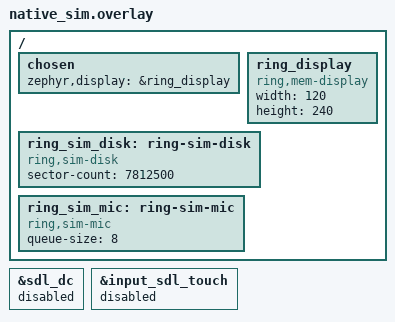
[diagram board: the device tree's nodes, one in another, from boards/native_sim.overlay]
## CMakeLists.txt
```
cmake_minimum_required(VERSION 3.20.0)

# The recorder's suites (software step 6, unit J): the real core, glue, screens and every unit of step 6 on the simulated
# drivers of ring_rhw. RING_RECORDER_DIR lets broken_run.sh point at a broken copy of ring_recorder to prove that these tests
# can fail: west twister ... --extra-args RING_RECORDER_DIR=<copy>
set(MOD ${CMAKE_CURRENT_SOURCE_DIR}/../../modules)
if(NOT DEFINED RING_RECORDER_DIR)
  set(RING_RECORDER_DIR ${MOD}/ring_recorder)
endif()
list(APPEND ZEPHYR_EXTRA_MODULES ${MOD}/ring_rhw ${MOD}/ring_core ${MOD}/ring_control ${MOD}/ring_devices ${MOD}/ring_inbox
  ${MOD}/ring_time ${MOD}/ring_iphone ${MOD}/ring_glue ${MOD}/ring_screens ${MOD}/ring_store ${MOD}/ring_audio
  ${MOD}/ring_xfer ${MOD}/ring_power ${MOD}/ring_motor ${MOD}/ring_sys ${MOD}/ring_factory ${RING_RECORDER_DIR})

find_package(Zephyr REQUIRED HINTS $ENV{ZEPHYR_BASE})
project(ring_recorder_tests)

target_include_directories(app PRIVATE src)
# RT_SUITE=<file> (without .c) builds the harness and that one suite file only: broken_run.sh uses it so that each broken
# copy runs the suite of its named case.
if(DEFINED RT_SUITE)
  target_sources(app PRIVATE src/rt.c src/${RT_SUITE}.c)
else()
target_sources(app PRIVATE
  src/rt.c
  src/test_rows.c
  src/test_actions.c
  src/test_boot.c
  src/test_sign.c
  src/test_sign1.c
  src/test_sequence.c
  src/test_rails.c
  src/test_rules.c
  src/test_log.c
  src/test_screens.c
  src/test_ship.c
  src/test_unmount.c
  src/test_factory.c
  src/test_noscreens.c)
endif()
```

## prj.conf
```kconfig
CONFIG_ZTEST=y
CONFIG_ZTEST_STACK_SIZE=16384
CONFIG_MAIN_STACK_SIZE=8192
CONFIG_THREAD_NAME=y
CONFIG_HEAP_MEM_POOL_SIZE=4096

# the glue needs the control part, which needs Bluetooth with the HID service (as in the product); nothing here enables
# Bluetooth (no bt_enable): the radio is not part of these suites
CONFIG_BT=y
CONFIG_BT_PERIPHERAL=y
CONFIG_BT_DEVICE_NAME="Ring"
CONFIG_BT_MAX_CONN=1
CONFIG_BT_MAX_PAIRED=3
CONFIG_BT_ID_MAX=3
CONFIG_BT_SMP=y
CONFIG_BT_SMP_SC_ONLY=y
CONFIG_BT_SMP_APP_PAIRING_ACCEPT=y
CONFIG_BT_GATT_AUTO_SEC_REQ=n
CONFIG_BT_AUTO_PHY_UPDATE=n
CONFIG_BT_HIDS_DEFAULT_PERM_RW_AUTHEN=y
CONFIG_BT_CONN_CTX=y
CONFIG_BT_HIDS=y
CONFIG_BT_HIDS_INPUT_REP_MAX=3
CONFIG_BT_HIDS_OUTPUT_REP_MAX=0
CONFIG_BT_HIDS_FEATURE_REP_MAX=0
CONFIG_BT_HIDS_ATTR_MAX=24
CONFIG_BT_HIDS_MAX_CLIENT_COUNT=1
CONFIG_BT_GATT_UUID16_POOL_SIZE=40
CONFIG_BT_GATT_CHRC_POOL_SIZE=20

CONFIG_RING_CORE=y
CONFIG_RING_DEVICES=y
CONFIG_RING_CONTROL=y
CONFIG_RING_GLUE=y
CONFIG_RING_GLUE_STACK_SIZE=8192
CONFIG_RING_INBOX=y
CONFIG_RING_TIME=y

# the screens on the memory display, with the read-back hooks
CONFIG_RING_SCREENS=y
CONFIG_RING_SCREENS_CAPTURE=y
CONFIG_RING_SCREENS_SIGN_WAIT_MS=2000
CONFIG_LVGL=y
CONFIG_LV_Z_AUTO_INIT=n
CONFIG_LV_COLOR_DEPTH_16=y
CONFIG_LV_FONT_MONTSERRAT_14=y
CONFIG_LV_FONT_MONTSERRAT_16=y
CONFIG_LV_FONT_MONTSERRAT_28=y
CONFIG_LV_FONT_MONTSERRAT_32=y
CONFIG_LV_Z_MEM_POOL_SIZE=32768
CONFIG_RING_SCREENS_STACK_SIZE=8192

# the recorder parts on the simulated drivers
CONFIG_RING_RHW=y
CONFIG_RING_RHW_SIM=y
CONFIG_RING_STORE=y
CONFIG_RING_AUDIO=y
CONFIG_RING_XFER=y
CONFIG_RING_POWER=y
CONFIG_RING_MOTOR=y
CONFIG_RING_SYS=y
CONFIG_RING_FACTORY=y
CONFIG_RING_RECORDER=y
CONFIG_RING_RECORDER_TEST_HOOKS=y
CONFIG_SYSTEM_WORKQUEUE_STACK_SIZE=4096
# a test card: each case starts on an empty card; the longest recording of a case (about 25 chunks) and the log fit
CONFIG_RING_RHW_SIM_DISK_POOL=6000
CONFIG_RING_RHW_SIM_LOG_SIZE=16384
```

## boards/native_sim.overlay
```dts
/* The recorder's suites: the memory display of the screens part (the SDL display of native_sim off), the simulated card and the
 * simulated microphone input of ring_rhw. No chip pin is named here. */
/ {
	chosen {
		zephyr,display = &ring_display;
	};
	ring_display: ring_display {
		compatible = "ring,mem-display";
		width = <120>;
		height = <240>;
	};
	ring_sim_disk: ring-sim-disk {
		compatible = "ring,sim-disk";
		sector-count = <7812500>;
	};
	ring_sim_mic: ring-sim-mic {
		compatible = "ring,sim-mic";
		queue-size = <8>;
	};
};

&sdl_dc {
	status = "disabled";
};

&input_sdl_touch {
	status = "disabled";
};
```

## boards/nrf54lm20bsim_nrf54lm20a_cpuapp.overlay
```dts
/* The recorder's suites on the simulated chip: the memory display of the screens part, the simulated card and the simulated
 * microphone input of ring_rhw. No chip pin is named here. */
/ {
	chosen {
		zephyr,display = &ring_display;
	};
	ring_display: ring_display {
		compatible = "ring,mem-display";
		width = <120>;
		height = <240>;
	};
	ring_sim_disk: ring-sim-disk {
		compatible = "ring,sim-disk";
		sector-count = <7812500>;
	};
	ring_sim_mic: ring-sim-mic {
		compatible = "ring,sim-mic";
		queue-size = <8>;
	};
};
```

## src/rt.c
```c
/* rt.c: the harness of the recorder's suites (see rt.h). */
#include <errno.h>
#include <string.h>

#include <zephyr/sys/byteorder.h>
#include <zephyr/sys/crc.h>

#include <ring_devices/rdev_logic.h>
#include <ring_inbox/rinbox.h>
#include <ring_iphone/ripl.h>
#include <ring_core/rc_sm.h>

#include "rt.h"

/* ------------------------------------------------------------------ logs of the wrappers */
#define STEPS_MAX 512
#define ACTS_MAX 1024
static struct rt_step steps[STEPS_MAX];
static uint32_t n_steps;
static struct rt_act acts[ACTS_MAX];
static uint32_t n_acts;
static uint32_t mic_at_screens;
static uint32_t screens_told;

uint32_t rt_steps(void)
{
	return MIN(n_steps, STEPS_MAX);
}

struct rt_step rt_step_get(uint32_t i)
{
	return steps[i];
}

bool rt_row_seen(int row)
{
	for (uint32_t i = 0; i < rt_steps(); i++) {
		if (steps[i].row == row) {
			return true;
		}
	}
	return false;
}

void rt_steps_clear(void)
{
	n_steps = 0;
	n_acts = 0;
	mic_at_screens = 0;
	screens_told = 0;
}

uint32_t rt_acts(void)
{
	return MIN(n_acts, ACTS_MAX);
}

struct rt_act rt_act_get(uint32_t i)
{
	return acts[i];
}

uint32_t rt_mic_at_screens(void)
{
	return mic_at_screens;
}

uint32_t rt_screens_told(void)
{
	return screens_told;
}

/* the product's glue ops (app/src/main.c), each wrapped to keep a log */
static void w_action(enum rc_action a, rc_ms_t t)
{
	if (n_acts < ACTS_MAX) {
		acts[n_acts].a = (uint8_t)a;
		acts[n_acts].t_ms = t;   /* the time of the core step the glue gives */
	}
	n_acts++;
	rrec_action(a, t);
}

static bool w_after(const struct rc_actions *a, enum rc_event ev, enum rc_state st, rc_ms_t t)
{
	if (n_steps < STEPS_MAX) {
		steps[n_steps].row = a->last_row;
		steps[n_steps].ev = (uint8_t)ev;
		steps[n_steps].state = (uint8_t)st;
		steps[n_steps].t_ms = k_uptime_get();
	}
	n_steps++;
	return rrec_glue_after(a, ev, st, t);
}

static const struct rglue_ops gops = {
	.action = w_action,
	.after = w_after,
	.screen_fact = rrec_glue_screen_fact,
	.sign_start = rrec_sign_hook,
	.factory_gesture = rrec_factory_gesture,
};

/* ------------------------------------------------------------------ stand-in reads of the screens (no inbox, no devices) */
static uint8_t o_inbox_count(void)
{
	return 0;
}

static bool o_inbox_get(uint8_t i, struct rinbox_item *o)
{
	ARG_UNUSED(i);
	ARG_UNUSED(o);
	return false;
}

static void o_media_get(struct ripl_media *o)
{
	ripl_media_init(o);
}

static bool o_ams_ready(void)
{
	return false;
}

/* called inside rscr_glue_after (load_view): the moment the screens learn of a core state */
static uint8_t o_paired(void)
{
	k_tid_t me = k_current_get();
	const char *nm = k_thread_name_get(me);

	if (me != rscr_thread_id() && (nm == NULL || strcmp(nm, "rpw") != 0)) {
		screens_told++;
		if (rc_core_state(rglue_core()) != RC_ST_RECORDING && rhw_pmic()->rail_get(RHW_RAIL_MIC) &&
		    atomic_get(&rrec_st.test_recording) == 0) {
			mic_at_screens++;
		}
	}
	return 0;
}

static uint8_t o_active(void)
{
	return RDEV_NONE;
}

static bool o_link(void)
{
	return false;
}

static int o_uid(uint32_t uid)
{
	ARG_UNUSED(uid);
	return 0;
}

static int o_slot(uint8_t slot)
{
	ARG_UNUSED(slot);
	return 0;
}

static void o_void(void)
{
}

static void o_bool(bool on)
{
	ARG_UNUSED(on);
}

static void o_mode(enum rctl_mode m)
{
	ARG_UNUSED(m);
}

static int o_power_off(void)
{
	return rglue_event_try(RC_EV_MENU_POWER_OFF);   /* the product's rule: -EBUSY when the glue is busy */
}

static const struct rscr_ops sops = {
	.inbox_count = o_inbox_count, .inbox_get = o_inbox_get, .media_get = o_media_get, .ams_ready = o_ams_ready,
	.paired_mask = o_paired, .active = o_active, .link_up = o_link, .dismiss = o_uid, .positive = o_uid,
	.mark_read = o_uid, .pair_open = o_slot, .pair_cancel = o_void, .dev_use = o_slot, .dev_remove = o_slot,
	.control_active = o_bool, .set_mode = o_mode, .power_off = o_power_off, .vibration = o_bool, .now_ms = NULL,
};

/* ------------------------------------------------------------------ world */
void rt_sleep(int32_t ms)
{
	k_sleep(K_MSEC(ms));
}

void rt_settle(void)
{
	int quiet = 0;

	for (int i = 0; i < 1000 && quiet < 3; i++) {
		k_sleep(K_MSEC(20));
		quiet = rrec_idle() ? quiet + 1 : 0;
	}
}

static bool glue_started;
bool rt_screens_started;

void rt_setup(void)
{
	if (!rt_screens_started) {
		rt_screens_started = true;
		zassert_equal(rscr_start(&sops), 0, "screens start on the memory display");
	}
	if (!glue_started) {
		glue_started = true;
		rglue_init(&gops, RC_ST_BOOT);
	}
}

void rt_setup_no_screens(void)
{
	if (!glue_started) {
		glue_started = true;
		rglue_init(&gops, RC_ST_BOOT);
	}
}

void rt_core_at(enum rc_state s)
{
	rc_core_init(rglue_core(), RC_CENTRE_SW2, s, k_uptime_get());
	rc_core_set_sign_hook(rglue_core(), rrec_sign_hook, NULL);
	rrec_st.core_state = (uint8_t)s;
}

static void apply(const struct rt_boot *b)
{
	static struct rhw_pmic_sample sc[2];
	struct rhw_persist p;

	if (b == NULL) {
		return;
	}
	if (b->chunks != 0) {
		rhw_sim_disk_set_sectors(RREC_LBA_CHUNK_FIRST + b->chunks * RREC_CHUNK_SECTORS);
	}
	if (b->init_fail != 0) {
		rhw_sim_disk_fail_init(b->init_fail);
	}
	if (b->mv != 0) {
		for (int i = 0; i < 2; i++) {
			sc[i].mv = i == 0 ? b->mv : (b->mv_next != 0 ? b->mv_next : b->mv);
			sc[i].ua = b->ua != 0 ? b->ua : 3000;
			sc[i].temp_c_x10 = 250;
			sc[i].die_c_x10 = 300;
		}
		rhw_sim_pmic_script(sc, 2);
	}
	if (b->chg_forced != 0) {
		rhw_sim_pmic_charge_state((int)b->chg_forced - 1);
	}
	if (b->gauge_uah != 0) {
		rhw_sim_gauge_capacity(b->gauge_uah);
	}
	if (b->soc_x10 != 0) {
		rhw_sim_gauge_start_soc(b->soc_x10);
	}
	if (b->factory_flag) {
		memset(&p, 0, sizeof(p));
		p.factory_flag = 1;
		rhw_sim_persist_set(&p);
	}
	if (b->vbus) {
		rhw_sim_pmic_vbus(true);
	}
	if (b->unconfirmed) {
		rhw_sim_image_set_confirmed(false);
	}
}

static void boot_now(const struct rt_boot *b)
{
	rhw_sim_log_clear();
	rrec_tap_clear();
	rt_steps_clear();
	rt_core_at(RC_ST_BOOT);
	(void)rrec_boot();
	if (b != NULL && b->vbus) {
		rhw_sim_usb_event(RHW_USB_VBUS_READY);   /* the controller reports VBUS at its start (the class enables the stack) */
	}
	rt_settle();
}

void rt_fresh(const struct rt_boot *b)
{
	rt_settle();
	rmd_inject_fail(0);
	rscr_test_force_down(false);
	rt_sleep(50);
	rhw_sim_reset();
	rhw_sim_reboot();   /* every unit's RAM state back to reset values (the audio part waits for its capture loop, F1) */
	apply(b);
	boot_now(b);
}

void rt_reboot(const struct rt_boot *b)
{
	rt_sleep(100);
	rhw_sim_reboot();   /* the audio part waits for its capture loop (finding F1): no sleep after it */
	apply(b);
	boot_now(b);
}

void rt_long(void)
{
	rglue_input(RC_SW_CENTRE, true);
	rt_sleep(1100);
	rglue_input(RC_SW_CENTRE, false);
	rt_sleep(100);
	rt_settle();
}

void rt_short(void)
{
	rglue_input(RC_SW_CENTRE, true);
	rt_sleep(100);
	rglue_input(RC_SW_CENTRE, false);
	rt_sleep(500);
	rt_settle();
}

void rt_double(void)
{
	rglue_input(RC_SW_CENTRE, true);
	rt_sleep(100);
	rglue_input(RC_SW_CENTRE, false);
	rt_sleep(150);
	rglue_input(RC_SW_CENTRE, true);
	rt_sleep(100);
	rglue_input(RC_SW_CENTRE, false);
	rt_sleep(500);
	rt_settle();
}

void rt_vbus(bool on)
{
	rhw_sim_vbus(on);
	rt_sleep(50);
	rt_settle();
}

void rt_usb_ready(void)
{
	rhw_sim_usb_event(RHW_USB_VBUS_READY);
	rt_settle();
}

void rt_usb_configured(void)
{
	rhw_sim_usb_event(RHW_USB_CONFIGURED);
	rt_sleep(20);
	rt_settle();
}

int rt_usb_send(uint8_t op, const uint8_t *pl, uint32_t len)
{
	static uint8_t req[RREC_MSG_HEADER_BYTES + RREC_FW_DATA_MAX + 16];
	static uint32_t tag = 0x1000;
	static uint8_t junk[256];

	while (rhw_sim_usb_host_read(junk, sizeof(junk)) > 0) {
	}
	tag++;
	sys_put_le16(RREC_MSG_MAGIC, &req[RREC_MSG_OFF_MAGIC]);
	req[RREC_MSG_OFF_OPCODE] = op;
	req[RREC_MSG_OFF_STATUS] = 0;
	sys_put_le32(tag, &req[RREC_MSG_OFF_TAG]);
	sys_put_le32(len, &req[RREC_MSG_OFF_LENGTH]);
	sys_put_le32(len != 0 ? crc32_ieee(pl, len) : 0, &req[RREC_MSG_OFF_CRC]);
	if (len != 0) {
		memcpy(&req[RREC_MSG_HEADER_BYTES], pl, len);
	}
	return rhw_sim_usb_host_write(req, RREC_MSG_HEADER_BYTES + len);
}

int rt_usb_recv(uint8_t *resp, size_t max, uint8_t *st, int32_t timeout_ms)
{
	size_t n = 0;
	uint32_t want;

	for (int32_t w = 0; w < timeout_ms; w += 10) {
		k_sleep(K_MSEC(10));
		n += rhw_sim_usb_host_read(&resp[n], max - n);
		if (n >= RREC_MSG_HEADER_BYTES) {
			want = RREC_MSG_HEADER_BYTES + sys_get_le32(&resp[RREC_MSG_OFF_LENGTH]);
			if (n >= want || n >= max) {
				break;
			}
		}
	}
	*st = n >= RREC_MSG_HEADER_BYTES ? resp[RREC_MSG_OFF_STATUS] : 0xFE;
	return (int)n;
}

int rt_usb(uint8_t op, const uint8_t *pl, uint32_t len, uint8_t *resp, size_t max, uint8_t *st)
{
	int n;

	if (rt_usb_send(op, pl, len) != 0) {
		*st = 0xFF;
		return -ENODEV;
	}
	n = rt_usb_recv(resp, max, st, 15000);
	rt_sleep(20);
	rt_settle();
	return n;
}

void rt_samples(uint16_t mv)
{
	static struct rhw_pmic_sample s;

	s.mv = mv;
	s.ua = 3000;
	s.temp_c_x10 = 250;
	s.die_c_x10 = 300;
	rhw_sim_pmic_script(&s, 1);
}

enum rc_state rt_state(void)
{
	/* read without the glue's lock: ship mode holds the lock while it waits for VBUS removal (FW l.939) */
	return rc_core_state(rglue_core());
}

bool rt_mic(void)
{
	return rhw_pmic()->rail_get(RHW_RAIL_MIC);
}

bool rt_sd(void)
{
	return rhw_pmic()->rail_get(RHW_RAIL_SD);
}

/* ------------------------------------------------------------------ the simulated event log */
int32_t rt_find(uint16_t kind, int64_t a0, int64_t a1, uint32_t from)
{
	struct rhw_sim_ev e;

	for (uint32_t i = from; rhw_sim_log_get(i, &e); i++) {
		if (e.kind == kind && (a0 < 0 || e.a0 == a0) && (a1 < 0 || e.a1 == a1)) {
			return (int32_t)i;
		}
	}
	return -1;
}

int32_t rt_find_rail(enum rhw_rail rail, bool on, uint32_t from)
{
	return rt_find(RHW_EV_PMIC_RAIL, rail, on ? 1 : 0, from);
}

int64_t rt_ev_us(int32_t i)
{
	struct rhw_sim_ev e;

	if (i < 0 || !rhw_sim_log_get((uint32_t)i, &e)) {
		return -1;
	}
	return e.t_us;
}

uint32_t rt_count_rail(enum rhw_rail rail, bool on)
{
	uint32_t n = 0;

	for (int32_t i = rt_find_rail(rail, on, 0); i >= 0; i = rt_find_rail(rail, on, (uint32_t)i + 1)) {
		n++;
	}
	return n;
}

/* ------------------------------------------------------------------ the display */
static uint8_t pic[RSCR_W * RSCR_H * 3];

bool rt_red_dot(void)
{
	int n = 0;

	rscr_sync();
	rscr_capture_rgb(pic);
	/* the red dot of SCR_RECORDING and SCR_REC_DIM: x 14 to 30, y 84 to 100 (tests/screens, test_draw.c) */
	for (int y = 84; y <= 100; y++) {
		for (int x = 14; x <= 30; x++) {
			const uint8_t *p = &pic[(y * RSCR_W + x) * 3];

			n += (p[0] > 200 && p[1] < 100 && p[2] < 100) ? 1 : 0;
		}
	}
	return n >= 40;
}

bool rt_blanked(void)
{
	struct rmd_stats m;

	rscr_sync();
	rmd_stats_get(&m);
	return m.blanked;
}

/* ------------------------------------------------------------------ rows of FW 1.2 */
const struct rc_row *rt_row(int row)
{
	for (uint16_t i = 0; i < rc_table_rows; i++) {
		if (rc_table[i].row == row) {
			return &rc_table[i];
		}
	}
	return NULL;
}

bool rt_cut_seen;

/* a card whose superblock says a recording was open: a recording, then the power cut (later writes lost) */
static void open_flag_card(void)
{
	rt_fresh(NULL);
	rt_long();
	rt_sleep(300);
	rhw_sim_disk_cut(1, 0);
	rt_sleep(800);
	rt_cut_seen = rhw_sim_disk_was_cut();   /* read before the reboot, which ends the cut (rhw_sim.h) */
}

/* the LBA of the open recording's first chunk, from the superblock on the simulated card (FW l.594, l.597, l.606, l.531):
 * the valid copy with the higher sb_seq (magic checked; the CRC is the store's business) */
static uint32_t open_first_chunk_lba(void)
{
	static uint8_t s[2][RREC_SECTOR_BYTES];
	int pick = -1;

	rhw_sim_disk_peek(RREC_LBA_SB_A, s[0]);
	rhw_sim_disk_peek(RREC_LBA_SB_B, s[1]);
	for (int i = 0; i < 2; i++) {
		if (sys_get_le32(&s[i][RREC_SB_OFF_MAGIC]) != RREC_SB_MAGIC) {
			continue;
		}
		if (pick < 0 || sys_get_le32(&s[i][RREC_SB_OFF_SB_SEQ]) > sys_get_le32(&s[pick][RREC_SB_OFF_SB_SEQ])) {
			pick = i;
		}
	}
	if (pick < 0) {
		return RREC_LBA_CHUNK_FIRST;
	}
	return RREC_LBA_CHUNK_FIRST + (sys_get_le32(&s[pick][RREC_SB_OFF_OPEN_FIRST_CHUNK]) %
				       sys_get_le32(&s[pick][RREC_SB_OFF_CHUNK_COUNT_TOTAL])) * RREC_CHUNK_SECTORS;
}

static void to_transfer(void)
{
	rt_vbus(true);
	rt_usb_configured();
}

static void fw_end_sequence(void)
{
	static uint8_t resp[64];
	static const uint8_t img[64] = { 1, 2, 3, 4, 5, 6, 7, 8 };
	uint8_t pl[8 + sizeof(img)];
	uint8_t st;

	sys_put_le32(sizeof(img), pl);
	sys_put_le32(crc32_ieee(img, sizeof(img)), &pl[4]);
	(void)rt_usb(RREC_OP_FW_BEGIN, pl, 8, resp, sizeof(resp), &st);
	sys_put_le32(0, pl);
	memcpy(&pl[4], img, sizeof(img));
	(void)rt_usb(RREC_OP_FW_DATA, pl, 4 + sizeof(img), resp, sizeof(resp), &st);
	(void)rt_usb(RREC_OP_FW_END, NULL, 0, resp, sizeof(resp), &st);
}

#if defined(CONFIG_RING_FACTORY)
static void factory_cmd(uint8_t sub)
{
	static uint8_t resp[512];
	uint8_t st;

	(void)rt_usb(RREC_OP_FACTORY, &sub, 1, resp, sizeof(resp), &st);
}

static void to_factory(void)
{
	struct rt_boot b = { .factory_flag = true };

	rt_fresh(&b);
	to_transfer();
	factory_cmd(RREC_FAC_ENTER);
}
#endif

static void mic_fault(void)
{
	rt_fresh(NULL);
	rt_long();
	for (int i = 0; i < 3 && rt_state() == RC_ST_RECORDING; i++) {
		uint32_t d = rhw_sim_mic_delivered();

		rhw_sim_mic_stop_after((int32_t)d + 2);
		rt_sleep(600);
		rt_settle();
		TC_PRINT("mic fault: try %d, blocks delivered %u, state %s, FAULT_MIC records %u, recorder idle %d\n", i + 1, d,
			 rc_state_name(rt_state()), rrec_tap_count_code(RREC_LOG_FAULT_MIC), rrec_idle());
	}
}

static void to_charger_error(void)
{
	struct rt_boot b = { .mv = 3900, .mv_next = 3250 };

	rt_fresh(&b);
	rt_vbus(true);
	rhw_sim_pmic_charge_error(1, 2);
	rt_sleep(50);
	rt_settle();
}

int rt_run_row(int row)
{
	struct rt_boot b;

	memset(&b, 0, sizeof(b));
	switch (row) {
	case 1:  /* SHIP, VBUS appears (the core's model; on the ring the chip starts from no power) */
	case 2:  /* OFF, VBUS appears */
		rt_fresh(NULL);
		rt_core_at(row == 1 ? RC_ST_SHIP : RC_ST_OFF);
		rt_steps_clear();
		rt_vbus(true);
		break;
	case 3:
		rt_fresh(NULL);
		break;
	case 4:
	case 9:
		open_flag_card();
		rt_reboot(NULL);
		break;
	case 5:
		b.vbus = true;
		rt_fresh(&b);
		break;
	case 6:
		b.init_fail = 3;
		rt_fresh(&b);
		break;
	case 7:
		b.mv = 3250;     /* at or under 3.30 V: B2 (FW l.117) */
		rt_fresh(&b);
		break;
	case 8:
		b.mv = 3400;     /* at or under 3.45 V: B5 (FW l.116) */
		rt_fresh(&b);
		break;
	case 10:
		open_flag_card();
		b.vbus = true;
		rt_reboot(&b);
		break;
	case 11:
		open_flag_card();
		rhw_sim_disk_read_error_at(open_first_chunk_lba());   /* the first chunk the scan reads */
		TC_PRINT("row 11: read error set at LBA %u (the open recording's first chunk)\n", open_first_chunk_lba());
		rt_reboot(NULL);
		break;
	case 12:
		rt_fresh(NULL);
		rt_long();
		break;
	case 13:  /* STANDBY with the open flag set (the fact the caller owns) */
		rt_fresh(NULL);
		rrec_st.fact_open = true;
		rrec_st.fact_open_pending = true;
		rt_long();
		break;
	case 14:  /* STANDBY with the battery fact at B5 */
		rt_fresh(NULL);
		rglue_core()->facts.batt = RC_BATT_B5;
		rt_long();
		break;
	case 15:  /* STANDBY with free space at SFULL: a card of 16 chunks, the core started in STANDBY with the fact */
		b.chunks = RREC_SFULL_CHUNKS;
		rt_fresh(&b);
		rt_core_at(RC_ST_STANDBY);
		rglue_core()->facts.storage_full = true;
		rt_long();
		break;
	case 16:
		rt_fresh(NULL);
		rscr_test_force_down(true);   /* the screens refuse the sign */
		rt_long();
		break;
	case 17:
		rt_fresh(NULL);
		rt_short();
		break;
	case 18:
		rt_fresh(NULL);
		rt_double();
		break;
	case 19:
		rt_fresh(NULL);
		rglue_event(RC_EV_MENU_POWER_OFF);
		rt_settle();
		break;
	case 20:
		rt_fresh(NULL);
		rt_vbus(true);
		break;
	case 21:
		b.soc_x10 = 151;   /* just above 15 % (FW l.115) */
		b.gauge_uah = 1000;
		rt_fresh(&b);
		rt_sleep(61000);
		rt_settle();
		break;
	case 22:
		b.mv = 3900;
		b.mv_next = 3400;
		rt_fresh(&b);
		rt_sleep(61000);
		rt_settle();
		break;
	case 23:
		b.mv = 3900;
		b.mv_next = 3250;
		rt_fresh(&b);
		rt_sleep(61000);
		rt_settle();
		break;
	case 24:
		b.chunks = RREC_SFULL_CHUNKS;
		rt_fresh(&b);
		break;
	case 25:
		b.init_fail = 1000;
		rt_fresh(&b);
		rt_vbus(true);
		rt_vbus(false);
		break;
	case 26:
		rt_fresh(NULL);
		rt_long();
		rt_sleep(1000);
		rt_long();
		break;
	case 27:
		rt_fresh(NULL);
		rt_long();
		rt_short();
		break;
	case 28:
		rt_fresh(NULL);
		rt_long();
		rt_double();
		break;
	case 29:
		rt_fresh(NULL);
		rt_long();
		rglue_event(RC_EV_BLE_HIGHLIGHT);
		rt_settle();
		break;
	case 30:
		rt_fresh(NULL);
		rt_long();
		rt_vbus(true);
		break;
	case 31:
		b.soc_x10 = 151;
		b.gauge_uah = 1000;
		rt_fresh(&b);
		rt_long();
		rt_sleep(5000);
		rt_settle();
		break;
	case 32:
		b.mv = 3900;
		b.mv_next = 2900;   /* mean of the two (3,400 mV) at or under 3.45 V (FW l.116, l.114) */
		rt_fresh(&b);
		rt_long();
		rt_sleep(2500);
		rt_settle();
		break;
	case 33:
		b.mv = 3900;
		b.mv_next = 2500;   /* mean of the two (3,200 mV) at or under 3.30 V (FW l.117) */
		rt_fresh(&b);
		rt_long();
		rt_sleep(2500);
		rt_settle();
		break;
	case 34:
		b.chunks = RREC_S30_CHUNKS + 2;
		rt_fresh(&b);
		rt_long();
		rt_sleep(2500);
		rt_settle();
		break;
	case 35:
		b.chunks = RREC_SFULL_CHUNKS + 2;
		rt_fresh(&b);
		rt_long();
		rt_sleep(2500);
		rt_settle();
		break;
	case 36:
		rt_fresh(NULL);
		rt_long();
		rhw_sim_disk_fail_write(1, RREC_WRITE_TRIES);
		rt_sleep(1500);
		rt_settle();
		break;
	case 37:
		mic_fault();
		break;
	case 38:  /* stands for the cut: the event the core's table names */
		rt_fresh(NULL);
		rt_long();
		rglue_event(RC_EV_POWER_LOSS);
		rt_settle();
		break;
	case 39:
		rt_fresh(NULL);
		to_transfer();
		break;
	case 40:
		rt_fresh(NULL);
		rt_vbus(true);
		rt_vbus(false);
		break;
	case 41:
		b.chunks = RREC_SFULL_CHUNKS;
		b.vbus = true;
		rt_fresh(&b);
		rt_vbus(false);
		break;
	case 42:
		b.vbus = true;
		b.mv = 3250;
		rt_fresh(&b);
		rt_vbus(false);
		break;
	case 43:
		b.vbus = true;
		b.mv = 3400;
		rt_fresh(&b);
		rt_vbus(false);
		break;
	case 44:
		rt_fresh(NULL);
		rt_vbus(true);
		rhw_sim_pmic_charge_error(1, 2);
		rt_sleep(50);
		rt_settle();
		break;
	case 45:
		rt_fresh(NULL);
		rt_vbus(true);
		rt_long();
		break;
	case 46:
		rt_fresh(NULL);
		to_transfer();
		rhw_sim_usb_event(RHW_USB_UNCONFIGURED);
		rt_sleep(50);
		rt_settle();
		break;
	case 47:
		rt_fresh(NULL);
		to_transfer();
		rt_vbus(false);
		break;
	case 48:
		rt_fresh(NULL);
		to_transfer();
		fw_end_sequence();
		break;
	case 50:
		rt_fresh(NULL);
		to_transfer();
		rt_long();
		break;
	case 51:
		b.chunks = RREC_SFULL_CHUNKS;
		rt_fresh(&b);
		rt_vbus(true);
		break;
	case 52:
		b.chunks = RREC_SFULL_CHUNKS;
		rt_fresh(&b);
		rt_long();
		break;
	case 53:
		b.chunks = RREC_SFULL_CHUNKS;
		b.mv = 3900;
		b.mv_next = 3400;
		rt_fresh(&b);
		rt_sleep(61000);
		rt_settle();
		break;
	case 54:
		b.chunks = RREC_SFULL_CHUNKS;
		b.mv = 3900;
		b.mv_next = 3250;
		rt_fresh(&b);
		rt_sleep(61000);
		rt_settle();
		break;
	case 55:
		b.mv = 3400;
		rt_fresh(&b);
		rt_vbus(true);
		break;
	case 56:
		b.mv = 3400;
		rt_fresh(&b);
		rt_long();
		break;
	case 57:
		b.mv = 3400;
		b.mv_next = 3250;
		rt_fresh(&b);
		rt_sleep(61000);
		rt_settle();
		break;
	case 58:
		b.init_fail = 1000;
		rt_fresh(&b);
		rt_vbus(true);
		break;
	case 59:
	case 62:
		b.init_fail = 1000;
		rt_fresh(&b);
		rt_sleep(61000);
		rt_settle();
		break;
	case 60:
		open_flag_card();
		b.init_fail = RREC_INIT_TRIES;
		rt_reboot(&b);
		rt_sleep(61000);
		rt_settle();
		break;
	case 61:
		b.init_fail = RREC_INIT_TRIES;
		rt_fresh(&b);
		rt_sleep(61000);
		rt_settle();
		break;
	case 63:
		b.init_fail = 1000;
		b.mv = 3900;
		b.mv_next = 3250;
		rt_fresh(&b);
		rt_sleep(61000);
		rt_settle();
		break;
	case 64:
		mic_fault();
		rt_sleep(5500);
		rt_settle();
		break;
	case 65:
		mic_fault();
		rt_vbus(true);
		break;
	case 66:  /* B2 inside the 5 s of ERR_MIC_FAULT: the level as the power part reports it (rglue_battery) */
		mic_fault();
		rglue_battery(RC_BATT_B2);
		rt_settle();
		break;
	case 67:
		to_charger_error();
		rt_vbus(false);
		break;
	case 68:
		to_charger_error();
		rt_sleep(61000);   /* the 60 s sample reads 3,250 mV: B2 with VBUS: ship mode waits for VBUS removal */
		break;
#if defined(CONFIG_RING_FACTORY)
	case 49:
		to_factory();
		break;
	case 69:
		to_factory();
		factory_cmd(RREC_FAC_EXIT);
		break;
	case 70:
		to_factory();
		factory_cmd(RREC_FAC_SHIP_ENTER);
		rt_sleep(500);
		break;
	case 71:
		to_factory();
		factory_cmd(RREC_FAC_SHIP_SAMPLE);
		rt_sleep(500);
		break;
	case 72:
		to_factory();
		rt_vbus(false);
		break;
#endif
	default:
		return -ENOTSUP;
	}
	return 0;
}

void rt_row_cleanup(int row)
{
	if (row == 68 || row == 70 || row == 71) {
		rhw_sim_vbus(false);   /* ship mode waits for VBUS removal (FW l.939) */
		rt_sleep(3000);
		rt_settle();
	}
}
```

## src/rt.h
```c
/*
 * rt.h: the harness of the recorder's suites (tests/recorder). The real core, glue (rglue), screens (memory display),
 * recorder and every unit of step 6 run on the simulated drivers of ring_rhw. The harness only observes: it wraps the
 * glue's ops of the product (rrec_action, rrec_glue_after, rrec_glue_screen_fact, rrec_sign_hook) to keep a log of
 * actions and steps, gives the screens a set of stand-in reads (no inbox, no devices), and drives the simulated
 * world (joystick edges through rglue_input, VBUS, USB requests, battery samples, card faults).
 * Expected values in the cases are typed from design/firmware.md ("FW l.N") or from the core's table (rc_table).
 */
#ifndef RT_H
#define RT_H

#include <stdbool.h>
#include <stdint.h>

#include <zephyr/kernel.h>
#include <zephyr/ztest.h>
#include <zephyr/sys/crc.h>

#include <ring_core/rc_core.h>
#include <ring_glue/rglue.h>
#include <ring_recorder/rrec.h>
#include <ring_rhw/rhw.h>
#include <ring_rhw/rhw_sim.h>
#include <ring_rhw/rrec_spec.h>
#include <ring_screens/rmd.h>
#include <ring_screens/rscr.h>
#include <ring_time/rtime.h>
#include <rrec_int.h>

/* ---- conditions of a boot ---- */
struct rt_boot {
	bool vbus;                /* VBUS present at power-up */
	uint16_t mv;              /* first battery sample in mV (0 = the simulated chip's 3,900 mV) */
	uint16_t mv_next;         /* the samples after the first (0 = same as mv) */
	uint16_t soc_x10;         /* gauge start (0 = the simulated gauge's 800) */
	uint32_t gauge_uah;       /* gauge capacity (0 = default) */
	uint32_t init_fail;       /* card init fails this many times */
	uint32_t chunks;          /* card with this many chunks (0 = the 4 GB card of FW l.654) */
	bool factory_flag;        /* persistent factory flag */
	bool unconfirmed;         /* the running image is not confirmed (the update self-test runs, FW l.1014) */
	int32_t ua;               /* with mv: the battery current of the samples in µA (0 = 3,000 µA discharge; < 0 charging) */
	uint8_t chg_forced;       /* 0 = the simulated charger's own state; else the charge state + 1 (RREC_CHG_* + 1) */
};

void rt_setup(void);                          /* once: screens and glue started */
void rt_setup_no_screens(void);               /* the glue only (the screens part never started), for recorder_a_noscreens */
extern bool rt_screens_started;               /* rt_setup started the screens part */
void rt_fresh(const struct rt_boot *b);       /* empty world, then a boot through rrec_boot() (NULL = defaults) */
void rt_reboot(const struct rt_boot *b);      /* rhw_sim_reboot(): the card, settings and retained memory kept */
void rt_core_at(enum rc_state s);             /* the core (and the join's copy) put in state s directly */
void rt_settle(void);                         /* the recorder's thread idle and the units quiet */
void rt_sleep(int32_t ms);

/* joystick, through rglue_input (the joystick driver's entry) */
void rt_long(void);                           /* centre held 1,100 ms */
void rt_short(void);
void rt_double(void);
/* VBUS (power chip and USB transport events), USB bus events */
void rt_vbus(bool on);
void rt_usb_ready(void);
void rt_usb_configured(void);
/* a USB request as the case writes it (FW 6.2): returns the response length (header included), status in *st */
int rt_usb(uint8_t op, const uint8_t *pl, uint32_t len, uint8_t *resp, size_t max, uint8_t *st);
/* the two halves of rt_usb: send without waiting; wait up to timeout_ms for the whole response */
int rt_usb_send(uint8_t op, const uint8_t *pl, uint32_t len);
int rt_usb_recv(uint8_t *resp, size_t max, uint8_t *st, int32_t timeout_ms);
/* charger, battery: the next sample(s) of the simulated power chip */
void rt_samples(uint16_t mv);

enum rc_state rt_state(void);
bool rt_mic(void);
bool rt_sd(void);

/* ---- the log of steps (test wrapper of rrec_glue_after) and actions (wrapper of rrec_action) ---- */
struct rt_step {
	int16_t row;
	uint8_t ev;
	uint8_t state;
	int64_t t_ms;
};
uint32_t rt_steps(void);
struct rt_step rt_step_get(uint32_t i);
bool rt_row_seen(int row);
void rt_steps_clear(void);
struct rt_act {
	uint8_t a;
	int64_t t_ms;
};
uint32_t rt_acts(void);
struct rt_act rt_act_get(uint32_t i);
/* the screens learned of a state other than RECORDING while VDD_MIC was on (a stand-in read of the screens, called
 * inside rscr_glue_after, counts it) */
uint32_t rt_mic_at_screens(void);
uint32_t rt_screens_told(void);

/* ---- the simulated event log ---- */
int32_t rt_find(uint16_t kind, int64_t a0, int64_t a1, uint32_t from);   /* a0/a1 = -1: any */
int32_t rt_find_rail(enum rhw_rail rail, bool on, uint32_t from);
int64_t rt_ev_us(int32_t i);
uint32_t rt_count_rail(enum rhw_rail rail, bool on);

/* ---- the display ---- */
bool rt_red_dot(void);                         /* the frame holds the red dot (40 px or more, as in tests/screens) */
bool rt_blanked(void);

/* ---- rows of FW 1.2: reach the From state and fire the event (shared by recorder_rows and recorder_sign1) ---- */
/* 0 = done; -ENOTSUP = the row needs a part not built (then the case says so) */
int rt_run_row(int row);
/* undo what a row left that blocks (ship mode waiting for VBUS removal) */
void rt_row_cleanup(int row);
const struct rc_row *rt_row(int row);
/* the power cut of the last open-flag card happened (read before its reboot) */
extern bool rt_cut_seen;

#endif
```

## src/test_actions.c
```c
/*
 * recorder_actions: the actions of the core carried out by the recorder (plan rows C4, C5, C12, C13, C19, C25, C27, A18
 * J part, P12). Orders are read from the one event log of the simulated drivers (rhw_sim.h).
 */
#include <string.h>

#include <zephyr/sys/byteorder.h>

#include <ring_store/rst.h>

#include "rt.h"

static bool in_range(int64_t lba, uint32_t lo, uint32_t hi)
{
	return lba >= lo && lba <= hi;
}

/* the first disk write at or after `from` whose LBA lies in [lo, hi] */
static int32_t find_write(uint32_t lo, uint32_t hi, uint32_t from)
{
	struct rhw_sim_ev e;

	for (uint32_t i = from; rhw_sim_log_get(i, &e); i++) {
		if (e.kind == RHW_EV_DISK_WRITE && in_range(e.a0, lo, hi)) {
			return (int32_t)i;
		}
	}
	return -1;
}

static int64_t act_time(enum rc_action a)
{
	for (uint32_t i = 0; i < rt_acts(); i++) {
		if (rt_act_get(i).a == a) {
			return rt_act_get(i).t_ms;
		}
	}
	return -1;
}

/* the frames of the closed recording against what the simulated input delivered (review finding R6-05): every kept frame
 * is the input's frame counter (left) and its inverse (right) from frame 800 on (FW l.460: the first 50 ms dropped), none
 * missing; the chunks' frames add up to the CLOSE record's duration; the last chunk is the partial one; and the duration
 * is what was captured from the start to the mark */
static void check_closed_frames(int64_t start_ms, int64_t mark_ms)
{
	static uint8_t chunk[RREC_CHUNK_BYTES];
	struct rst_mount_info mi;
	struct rst_rec_info info[8];
	uint16_t n = 0;
	uint64_t sum = 0;
	uint32_t last_frames = 0;
	uint32_t bad = 0;
	int64_t want;

	zassert_equal(rst_mount(false, &mi), 0, "mount");
	zassert_equal(rst_list(0, 8, info, &n), 0, "list");
	zassert_true(n >= 1, "the recording is listed");
	for (uint32_t c = 0; c < info[n - 1].chunk_count; c++) {
		uint32_t fr;
		const uint8_t *pl = &chunk[RREC_CHUNK_HEADER_BYTES];

		zassert_equal(rst_read_chunk(info[n - 1].recording_id, c, chunk), 0, "read chunk %u", c);
		fr = sys_get_le32(&chunk[RREC_CH_OFF_FRAMES]);
		for (uint32_t f = 0; f < fr; f++) {
			uint16_t want_l = (uint16_t)((RREC_DISCARD_FRAMES + sum + f) & 0xFFFFu);
			uint16_t l = sys_get_le16(&pl[f * 4]);
			uint16_t r = sys_get_le16(&pl[f * 4 + 2]);

			if (l != want_l || r != (uint16_t)~want_l) {
				if (bad < 3) {
					TC_PRINT("close frames: chunk %u frame %u: %u/%u, captured %u/%u\n", c, f, l, r, want_l,
						 (uint16_t)~want_l);
				}
				bad++;
			}
		}
		sum += fr;
		last_frames = fr;
	}
	(void)rst_unmount();
	/* FW l.443, l.460: 16 frames per ms; the kept frames run from the start + 50 ms to the mark */
	want = (mark_ms - start_ms) * 16 - (int64_t)RREC_DISCARD_FRAMES;
	TC_PRINT("close frames: %u chunks, %llu frames in the chunks, CLOSE duration %llu, last chunk %u frames, "
		 "captured to the mark %lld (start %lld ms, mark %lld ms), %u frames not as captured\n", info[n - 1].chunk_count,
		 sum, info[n - 1].duration_frames, last_frames, want, start_ms, mark_ms, bad);
	zassert_equal(bad, 0, "every kept frame is the captured one (%u not)", bad);
	zassert_equal(sum, info[n - 1].duration_frames, "the chunks hold the whole duration (%llu of %llu)", sum,
		      info[n - 1].duration_frames);
	zassert_true(last_frames > 0 && last_frames < RREC_CHUNK_FRAMES, "the last chunk is the partial one (%u)",
		     last_frames);
	/* one block (256 frames, FW l.443) plus one ms of each stamp: the mark and the start are ms times */
	zassert_true(sum + RREC_BLOCK_FRAMES + 32 >= (uint64_t)want && sum <= (uint64_t)want + RREC_BLOCK_FRAMES + 32,
		     "kept %llu, captured to the mark %lld", sum, want);
}

/* FW l.125: close = partial chunk, CLOSE record, superblock flag clear, stop PDM, clocks low, VDD_MIC off, VDD_SD off */
ZTEST(recorder_actions, test_close_order)
{
	int32_t i_part, i_close, i_sb, i_stop, i_sleep, i_mic, i_sd;
	int64_t start_ms, mark_ms;

	rt_fresh(NULL);
	rhw_sim_log_clear();
	rt_long();
	start_ms = rt_ev_us(rt_find(RHW_EV_MIC_START, -1, -1, 0)) / 1000;
	zassert_true(start_ms > 0, "the input started");
	rt_sleep(1300);
	/* the stop press so that its mark (1,000 ms after the press, FW l.128) falls in the middle of a chunk: a partial
	 * chunk of about half a chunk exists (8,192 frames, FW l.535) */
	for (int i = 0; i < 200; i++) {
		int64_t at_mark = (k_uptime_get() + RREC_LONG_PRESS_MS - start_ms) * 16 - (int64_t)RREC_DISCARD_FRAMES;
		int64_t in_chunk = at_mark % RREC_CHUNK_FRAMES;

		if (in_chunk >= 3000 && in_chunk <= 5000) {
			break;
		}
		rt_sleep(4);
	}
	rhw_sim_log_clear();
	rt_steps_clear();
	rt_long();
	zassert_equal(rt_state(), RC_ST_STANDBY, "stopped");
	mark_ms = act_time(RC_ACT_CLOSE);
	zassert_true(mark_ms > start_ms, "CLOSE carried out");
	i_part = find_write(RREC_LBA_CHUNK_FIRST, UINT32_MAX, 0);
	i_close = find_write(RREC_LBA_INDEX_FIRST, RREC_LBA_INDEX_LAST, 0);
	i_sb = find_write(RREC_LBA_SB_A, RREC_LBA_SB_B, i_close < 0 ? 0 : (uint32_t)i_close);
	i_stop = rt_find(RHW_EV_MIC_STOP, -1, -1, 0);
	i_sleep = rt_find(RHW_EV_MIC_PINS_SLEEP, -1, -1, i_stop < 0 ? 0 : (uint32_t)i_stop);
	i_mic = rt_find_rail(RHW_RAIL_MIC, false, 0);
	i_sd = rt_find_rail(RHW_RAIL_SD, false, 0);
	TC_PRINT("close order: chunk %d, CLOSE record %d, superblock %d, PDM stop %d, clocks low %d, VDD_MIC off %d, "
		 "VDD_SD off %d\n", i_part, i_close, i_sb, i_stop, i_sleep, i_mic, i_sd);
	zassert_true(i_part >= 0 && i_close > i_part, "partial chunk before the CLOSE record");
	zassert_true(i_sb > i_close, "superblock after the CLOSE record");
	zassert_true(i_stop > i_sb, "PDM stop after the superblock");
	zassert_true(i_sleep > i_stop, "clocks low after the stop");
	zassert_true(i_mic > i_sleep, "VDD_MIC off after the clocks are low");
	zassert_true(i_sd > i_mic, "VDD_SD off last");
	check_closed_frames(start_ms, mark_ms);
}

/* FW l.126: open = VDD_SD on, mount, superblock with the open flag, VDD_MIC on, PDM start (FW 4.5) */
ZTEST(recorder_actions, test_open_order)
{
	int32_t i_sd, i_init, i_sb, i_mic, i_cfg, i_start;

	rt_fresh(NULL);
	rhw_sim_log_clear();
	rt_long();
	zassert_equal(rt_state(), RC_ST_RECORDING, "recording");
	i_sd = rt_find_rail(RHW_RAIL_SD, true, 0);
	i_init = rt_find(RHW_EV_DISK_INIT, -1, -1, 0);
	i_sb = find_write(RREC_LBA_SB_A, RREC_LBA_SB_B, i_init < 0 ? 0 : (uint32_t)i_init);
	i_mic = rt_find_rail(RHW_RAIL_MIC, true, 0);
	i_cfg = rt_find(RHW_EV_MIC_CONFIGURE, -1, -1, 0);
	i_start = rt_find(RHW_EV_MIC_START, -1, -1, 0);
	TC_PRINT("open order: VDD_SD on %d, init %d, superblock %d, VDD_MIC on %d, configure %d, start %d\n", i_sd, i_init,
		 i_sb, i_mic, i_cfg, i_start);
	zassert_true(i_sd >= 0 && i_init > i_sd, "mount after VDD_SD on");
	zassert_true(i_sb > i_init, "superblock after the mount");
	zassert_true(i_mic > i_sb, "VDD_MIC on after the superblock");
	zassert_true(i_cfg > i_mic && i_start > i_cfg, "PDM configured and started after VDD_MIC on");
	rt_long();
}

/* FW l.158, l.448: a long press in RECORDING closes; M2 runs after VDD_MIC is off */
ZTEST(recorder_actions, test_stop_m2_after_mic_off)
{
	struct rhw_sim_ev e;
	int64_t t_close;
	int32_t i_off, i_first = -1;

	rt_fresh(NULL);
	rt_long();
	rt_sleep(1000);
	rhw_sim_log_clear();
	rt_steps_clear();
	rt_long();
	t_close = act_time(RC_ACT_CLOSE);
	zassert_true(t_close >= 0, "CLOSE carried out");
	i_off = rt_find_rail(RHW_RAIL_MIC, false, 0);
	for (uint32_t i = 0; rhw_sim_log_get(i, &e); i++) {
		if (e.kind == RHW_EV_MOTOR && e.a0 == 1 && e.t_us >= t_close * 1000) {
			i_first = (int32_t)i;
			break;
		}
	}
	TC_PRINT("stop: VDD_MIC off at %d (t %lld us), first MOTOR high from the press at %d (t %lld us)\n", i_off,
		 rt_ev_us(i_off), i_first, rt_ev_us(i_first));
	zassert_true(i_off >= 0 && i_first > i_off, "M2's MOTOR high comes after VDD_MIC off");
	zassert_true(rt_ev_us(i_first) >= rt_ev_us(i_off), "and not earlier in time");
}

/* FW l.144, l.447, ruling R21: M1 at the press, before storage is opened */
ZTEST(recorder_actions, test_m1_at_start)
{
	int32_t i_m1, i_sd;
	int64_t t_open;
	struct rhw_sim_ev e;

	rt_fresh(NULL);
	rhw_sim_log_clear();
	rt_long();
	t_open = act_time(RC_ACT_OPEN);
	i_sd = rt_find_rail(RHW_RAIL_SD, true, 0);
	i_m1 = -1;
	for (uint32_t i = 0; rhw_sim_log_get(i, &e); i++) {
		if (e.kind == RHW_EV_MOTOR && e.a0 == 1 && e.t_us >= t_open * 1000) {
			i_m1 = (int32_t)i;
			break;
		}
	}
	zassert_true(i_m1 >= 0 && i_m1 < i_sd, "M1's MOTOR high before VDD_SD on (%d, %d)", i_m1, i_sd);
	rt_long();
}

/* a recording's list entry after it closed (mounts the card for the read) */
static bool last_recording(struct rst_rec_info *out)
{
	struct rst_mount_info mi;
	struct rst_rec_info info[8];
	uint16_t n = 0;

	if (rst_mount(false, &mi) != 0) {
		return false;
	}
	(void)rst_list(0, 8, info, &n);
	(void)rst_unmount();
	if (n == 0) {
		return false;
	}
	*out = info[n - 1];
	return true;
}

/* FW l.159, l.161: a highlight by short press or by the Bluetooth "highlight", MH (C13) */
ZTEST(recorder_actions, test_ble_highlight_marks)
{
	struct rst_rec_info r;

	memset(&r, 0, sizeof(r));
	rt_fresh(NULL);
	rt_long();
	rt_sleep(700);
	rglue_event(RC_EV_BLE_HIGHLIGHT);
	rt_settle();
	zassert_true(rt_row_seen(29), "row 29");
	rt_sleep(600);
	rt_short();
	zassert_true(rt_row_seen(27), "row 27");
	rt_sleep(300);
	rt_long();
	zassert_true(last_recording(&r), "the recording is listed");
	zassert_equal(r.highlight_count, 2, "two highlights in the CLOSE record (%u)", r.highlight_count);
	zassert_true(rrec_tap_count_code(RREC_LOG_MOTOR_PATTERN) >= 3, "MH played");
}

/* FW l.229, l.265: a long press in CHARGING, TRANSFER, ERR_STORAGE_FULL, ERR_BATTERY_LOW: refused with M3 (C25) */
ZTEST(recorder_actions, test_refusal_plays_m3)
{
	static const int rows[] = { 45, 50, 52, 56 };

	for (size_t i = 0; i < ARRAY_SIZE(rows); i++) {
		struct rrec_tap_rec t;
		bool m3 = false;

		zassert_equal(rt_run_row(rows[i]), 0, NULL);
		zassert_true(rt_row_seen(rows[i]), "row %d", rows[i]);
		for (uint32_t k = 0; rrec_tap_get(k, &t); k++) {
			m3 |= t.code == RREC_LOG_MOTOR_PATTERN && t.args[0] == RREC_PAT_M3;
		}
		zassert_true(m3, "M3 played for row %d", rows[i]);
		zassert_false(rrec_st.recording, "no recording");
	}
}

/* FW l.191 to l.194, ruling R3: every 60 s the storage init runs and its result is reported (C19), both answers */
ZTEST(recorder_actions, test_retry_storage_reports_result)
{
	struct rt_boot b = { .init_fail = 1000 };
	struct rrec_tap_rec t;
	int fails = 0, oks = 0;

	rt_fresh(&b);
	zassert_equal(rt_state(), RC_ST_ERR_STORAGE_FAULT, "ERR_STORAGE_FAULT");
	rt_sleep(61000);
	rt_settle();
	zassert_true(rt_row_seen(59), "row 59: 60 s elapsed");
	zassert_true(rt_row_seen(62), "row 62: the failed retry reported");
	zassert_equal(rt_state(), RC_ST_ERR_STORAGE_FAULT, "stays");
	rhw_sim_disk_fail_init(0);   /* the card answers again */
	rt_sleep(60000);
	rt_settle();
	zassert_true(rt_row_seen(61), "row 61: the successful retry reported");
	zassert_equal(rt_state(), RC_ST_STANDBY, "STANDBY");
	for (uint32_t k = 0; rrec_tap_get(k, &t); k++) {
		if (t.code == RREC_LOG_STORAGE_RETRY) {
			if (sys_get_le32(t.args) == 0) {
				oks++;
			} else {
				fails++;
			}
		}
	}
	zassert_true(fails >= 1 && oks == 1, "retry results logged: %d failed, %d ok", fails, oks);
}

/* FW l.498: MW in a recording is marked like every pulse (A18, the join's part: the motor edges reach the audio part) */
ZTEST(recorder_actions, test_mw_in_recording_marked)
{
	static uint8_t chunk[RREC_CHUNK_BYTES];
	struct rst_mount_info mi;
	struct rst_rec_info info[4];
	uint16_t n = 0;
	int marked_later = 0;

	rt_fresh(NULL);
	rt_long();
	rt_sleep(1500);
	rglue_input(RC_SW_CENTRE, true);   /* held 600 ms: MW at 500 ms (FW l.241), no long press */
	rt_sleep(600);
	rglue_input(RC_SW_CENTRE, false);
	rt_sleep(1500);
	rt_long();
	zassert_equal(rst_mount(false, &mi), 0, "mount");
	zassert_equal(rst_list(0, 4, info, &n), 0, "list");
	zassert_true(n >= 1, "one recording");
	for (uint32_t c = 1; c < info[n - 1].chunk_count; c++) {
		zassert_equal(rst_read_chunk(info[n - 1].recording_id, c, chunk), 0, "read chunk %u", c);
		if (sys_get_le16(&chunk[RREC_CH_OFF_FLAGS]) & RREC_CH_FLAG_MOTOR) {
			marked_later++;
		}
	}
	(void)rst_unmount();
	zassert_true(marked_later >= 1, "a chunk after the first carries a motor interval (MW, MH or M2's edge)");
}

/* FW l.936 to l.941 step 1: close everything, save settings and time, before the ship steps (P12, the join's part) */
ZTEST(recorder_actions, test_ship_closes_everything_first)
{
	int32_t i_mic, i_sd, i_cfg, i_strobe, i_ship, i_save;

	zassert_equal(rt_run_row(33), 0, NULL);   /* a recording at B2: close; ship mode */
	i_mic = rt_find_rail(RHW_RAIL_MIC, false, 0);
	i_sd = rt_find_rail(RHW_RAIL_SD, false, i_mic < 0 ? 0 : (uint32_t)i_mic);
	i_cfg = rt_find(RHW_EV_PMIC_SHPHLD_CFG, -1, -1, 0);
	i_strobe = rt_find(RHW_EV_PMIC_SHPHLD_STROBE, -1, -1, 0);
	i_ship = rt_find(RHW_EV_PMIC_SHIP, -1, -1, 0);
	zassert_true(i_mic >= 0 && i_sd > i_mic && i_cfg > i_sd, "VDD_MIC off, VDD_SD off, then SHPHLDCONFIG");
	zassert_equal(rt_find(RHW_EV_PMIC_SHPHLD_CFG, RREC_SHPHLD_MS, -1, 0), i_cfg, "96 ms (FW l.938)");
	zassert_true(i_strobe > i_cfg && i_ship > i_strobe, "strobe, then the ship task");
	/* the menu's power off: settings and time saved before the ship steps */
	rt_fresh(NULL);
	rtime_set(1763000000000LL, 60, true);
	rhw_sim_log_clear();
	rglue_event(RC_EV_MENU_POWER_OFF);
	rt_settle();
	i_save = rt_find(RHW_EV_PERSIST_SAVE, -1, -1, 0);
	i_cfg = rt_find(RHW_EV_PMIC_SHPHLD_CFG, -1, -1, 0);
	zassert_true(rt_row_seen(19), "row 19");
	zassert_true(i_save >= 0 && i_cfg > i_save, "time saved before SHPHLDCONFIG (%d, %d)", i_save, i_cfg);
}

/* Review finding R6-08: an event of the kinds VBUS_OUT, MIC_NO_BLOCK, CHUNK_WRITE_FAILED that finds the recorder's queue
 * full is latched and reaches the core when the queue has room (rows 40, 37, 36 of FW 1.2) */
static int fill_queue_then_post(enum rc_event ev)
{
	int r;
	int n = 0;

	k_sched_lock();
	while (n < 100 && rrec_post(RREC_JOB_EVENT, RC_EV_INIT_DONE) == 0) {   /* no row outside BOOT: dropped by the core */
		n++;
	}
	r = rrec_post(RREC_JOB_EVENT, ev);
	k_sched_unlock();
	TC_PRINT("latch: %d jobs filled the queue, the post of event %d answered %d\n", n, ev, r);
	return r;
}

ZTEST(recorder_actions, test_latched_events_not_lost)
{
	rt_fresh(NULL);
	rt_vbus(true);
	zassert_equal(rt_state(), RC_ST_CHARGING, "CHARGING");
	rt_steps_clear();
	zassert_not_equal(fill_queue_then_post(RC_EV_VBUS_OUT), 0, "the queue was full");
	rt_settle();
	zassert_true(rt_row_seen(40), "row 40: VBUS removed reached the core (FW l.172)");
	zassert_equal(rt_state(), RC_ST_STANDBY, "STANDBY");

	rt_fresh(NULL);
	rt_long();
	zassert_equal(rt_state(), RC_ST_RECORDING, "recording");
	rt_steps_clear();
	zassert_not_equal(fill_queue_then_post(RC_EV_MIC_NO_BLOCK), 0, "the queue was full");
	rt_settle();
	zassert_true(rt_row_seen(37), "row 37: no block reached the core (FW l.169)");
	zassert_equal(rt_state(), RC_ST_ERR_MIC_FAULT, "ERR_MIC_FAULT");

	rt_fresh(NULL);
	rt_long();
	zassert_equal(rt_state(), RC_ST_RECORDING, "recording");
	rt_steps_clear();
	zassert_not_equal(fill_queue_then_post(RC_EV_CHUNK_WRITE_FAILED), 0, "the queue was full");
	rt_settle();
	zassert_true(rt_row_seen(36), "row 36: the write fault reached the core (FW l.168)");
	zassert_equal(rt_state(), RC_ST_ERR_STORAGE_FAULT, "ERR_STORAGE_FAULT");
}

/* FW l.218, l.1065 (C23, the join's part): during a recording the audio and storage threads report progress through the
 * join, so the watchdog is fed; the feed rule itself is the system unit's (sys_wdt.test_feed_only_with_progress) */
ZTEST(recorder_actions, test_watchdog_fed_while_recording)
{
	uint32_t f0, f1;

	rt_fresh(NULL);
	zassert_true(rhw_sim_wdt_started(), "the watchdog runs (8 s, FW l.1065)");
	rt_long();
	f0 = rhw_sim_wdt_feeds();
	rt_sleep(12000);   /* longer than the 8 s timeout */
	f1 = rhw_sim_wdt_feeds();
	TC_PRINT("watchdog feeds during 12 s of recording: %u\n", f1 - f0);
	zassert_true(f1 - f0 >= 10, "fed about once a second while recording (%u)", f1 - f0);
	zassert_false(rhw_sim_wdt_would_reset(), "never 8 s without a feed");
	rt_long();
}

static void *setup(void)
{
	rt_setup();
	return NULL;
}

ZTEST_SUITE(recorder_actions, NULL, setup, NULL, NULL, NULL);
```

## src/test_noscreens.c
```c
/*
 * recorder_a_noscreens: ship mode when the screens part never started (step 6 fix round 1, lead's ruling 4 on the open
 * point of rscr_sync() without a time limit). The suite's name sorts first, so ztest runs it before every suite that
 * starts the screens (rt_setup); the case checks that the screens were indeed never started.
 */
#include "rt.h"

/* FW l.151, l.936 to l.941: the menu's power off goes through all of ship mode although no screens thread exists */
ZTEST(recorder_a_noscreens, test_ship_without_screens_ends)
{
	int64_t t0;

	zassert_false(rt_screens_started, "this case runs before any suite started the screens part");
	rt_fresh(NULL);
	rhw_sim_log_clear();
	t0 = k_uptime_get();
	rglue_event(RC_EV_MENU_POWER_OFF);
	rt_settle();
	TC_PRINT("ship without screens: idle %d, SHPHLDCONFIG at %d, ship task at %d, %lld ms\n", rrec_idle(),
		 rt_find(RHW_EV_PMIC_SHPHLD_CFG, -1, -1, 0), rt_find(RHW_EV_PMIC_SHIP, -1, -1, 0), k_uptime_get() - t0);
	zassert_true(rrec_idle(), "ship mode ended (the recorder's thread is free)");
	zassert_true(rt_find(RHW_EV_PMIC_SHPHLD_CFG, -1, -1, 0) >= 0, "SHPHLDCONFIG written (FW l.938)");
	zassert_true(rhw_sim_shipped(), "the ship task written (FW l.940)");
}

static void *setup(void)
{
	rt_setup_no_screens();
	return NULL;
}

ZTEST_SUITE(recorder_a_noscreens, NULL, setup, NULL, NULL, NULL);
```
